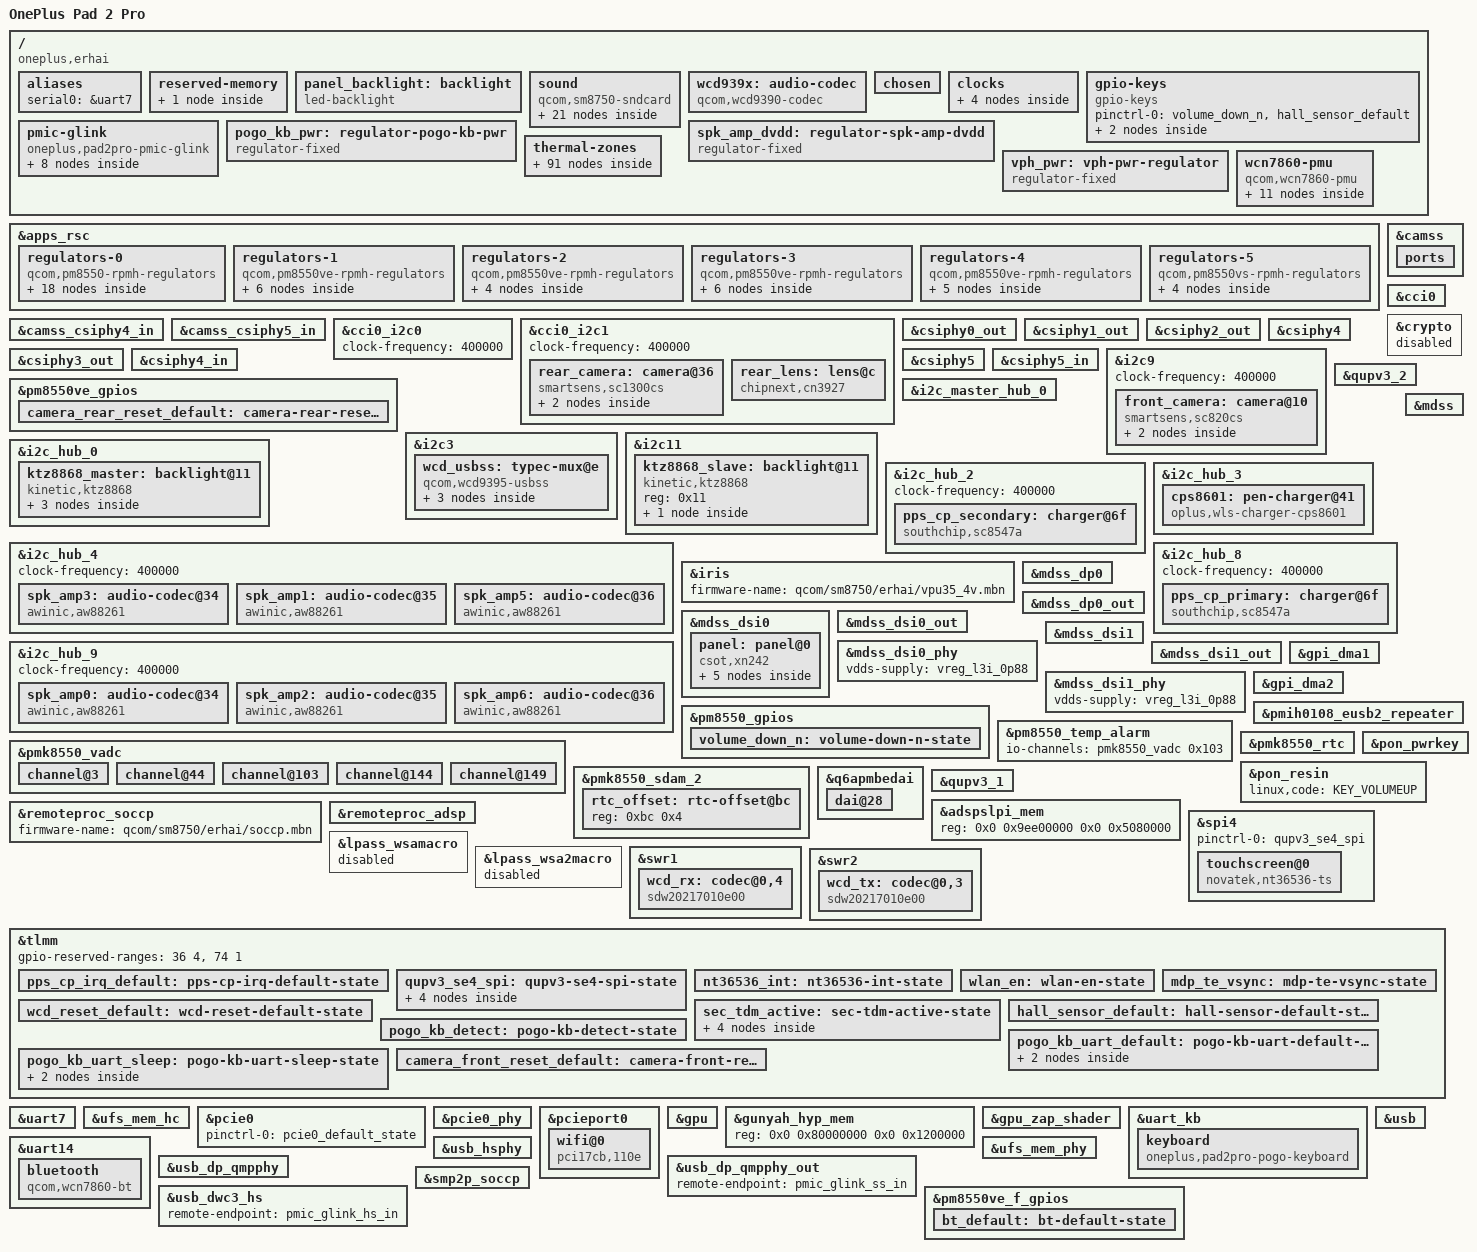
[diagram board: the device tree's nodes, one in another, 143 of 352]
// SPDX-License-Identifier: BSD-3-Clause
/*
 * Copyright (c) 2026, yzddmr6
 */

/dts-v1/;

#include <dt-bindings/clock/qcom,sm8750-cambistmclkcc.h>
#include <dt-bindings/gpio/gpio.h>
#include <dt-bindings/input/gpio-keys.h>
#include <dt-bindings/interrupt-controller/irq.h>
#include <dt-bindings/leds/common.h>
#include <dt-bindings/media/video-interfaces.h>
#include <dt-bindings/regulator/qcom,rpmh-regulator.h>
#include <dt-bindings/thermal/thermal.h>
#include "sm8750.dtsi"
#include "pm8550.dtsi"
#define PMK8550VE_SID 8
#include "pm8550ve.dtsi"
#include "pmih0108.dtsi"
#include "pmk8550.dtsi"
#include "sm8750-pmics.dtsi"

/delete-node/ &cpusys_vm_mem;

/ {
	model = "OnePlus Pad 2 Pro";
	compatible = "oneplus,erhai", "qcom,sm8750";
	chassis-type = "tablet";

	aliases {
		serial0 = &uart7;
	};

	reserved-memory {
		ramoops@afff00000 {
			compatible = "ramoops";
			reg = <0xa 0xfff00000 0x0 0x100000>;
			record-size = <0x20000>;
			console-size = <0x40000>;
			pmsg-size = <0x20000>;
		};
	};

	/*
	 * Both KTZ8868 chips light the one panel and always get the same
	 * brightness value. The initial level is the stock default brightness
	 * level 913 mapped through the stock kernel's backlight table.
	 */
	panel_backlight: backlight {
		compatible = "led-backlight";
		leds = <&ktz8868_master_led>, <&ktz8868_slave_led>;
		default-brightness-level = <1433>;
	};

	sound {
		compatible = "qcom,sm8750-sndcard", "qcom,sm8450-sndcard";
		model = "OnePlus-Pad-2-Pro";
		audio-routing = "IN1_HPHL", "HPHL_OUT",
				"IN2_HPHR", "HPHR_OUT",
				"AMIC1", "MIC BIAS1",
				"AMIC2", "MIC BIAS2",
				"AMIC3", "MIC BIAS4",
				"AMIC4", "MIC BIAS3",
				"AMIC5", "MIC BIAS3",
				"TX SWR_INPUT0", "ADC1_OUTPUT",
				"TX SWR_INPUT1", "ADC2_OUTPUT",
				"TX SWR_INPUT2", "ADC3_OUTPUT",
				"TX SWR_INPUT3", "ADC4_OUTPUT";

		pinctrl-0 = <&sec_tdm_active>;
		pinctrl-names = "default";

		displayport-0-dai-link {
			link-name = "DisplayPort0 Playback";
			convert-sample-format = "s24_le";

			cpu {
				sound-dai = <&q6apmbedai DISPLAY_PORT_RX_0>;
			};

			codec {
				sound-dai = <&mdss_dp0>;
			};

			platform {
				sound-dai = <&q6apm>;
			};
		};

		wcd-playback-dai-link {
			link-name = "WCD Playback";

			cpu {
				sound-dai = <&q6apmbedai RX_CODEC_DMA_RX_0>;
			};

			codec {
				sound-dai = <&wcd939x 0>, <&swr1 0>, <&lpass_rxmacro 0>;
			};

			platform {
				sound-dai = <&q6apm>;
			};
		};

		wcd-capture-dai-link {
			link-name = "WCD Capture";

			cpu {
				sound-dai = <&q6apmbedai TX_CODEC_DMA_TX_3>;
			};

			codec {
				sound-dai = <&wcd939x 1>, <&swr2 1>, <&lpass_txmacro 0>;
			};

			platform {
				sound-dai = <&q6apm>;
			};
		};

		/*
		 * Secondary TDM at 48 kHz: eight 32-bit slots, DSP_B framing,
		 * clocks from the SoC. Each amplifier takes the slot equal to
		 * its stock channel index and latches data on the inverted bit
		 * clock edge, as the stock amplifier configuration does.
		 */
		speaker-playback-dai-link {
			link-name = "Speaker Playback";
			dai-format = "dsp_b";
			convert-rate = <48000>;
			convert-channels = <8>;
			convert-sample-format = "s32_le";

			cpu {
				sound-dai = <&q6apmbedai SECONDARY_TDM_RX_0>;
				dai-tdm-slot-num = <8>;
				dai-tdm-slot-width = <32>;
				dai-tdm-slot-rx-mask = <1 1 1 1 1 1 1 1>;
			};

			codec-0 {
				sound-dai = <&spk_amp0>;
				dai-tdm-slot-tx-mask = <1>;
				dai-tdm-slot-rx-mask = <1>;
				bitclock-inversion;
			};

			codec-1 {
				sound-dai = <&spk_amp1>;
				dai-tdm-slot-tx-mask = <0 1>;
				dai-tdm-slot-rx-mask = <0 1>;
				bitclock-inversion;
			};

			codec-2 {
				sound-dai = <&spk_amp2>;
				dai-tdm-slot-tx-mask = <0 0 1>;
				dai-tdm-slot-rx-mask = <0 0 1>;
				bitclock-inversion;
			};

			codec-3 {
				sound-dai = <&spk_amp3>;
				dai-tdm-slot-tx-mask = <0 0 0 1>;
				dai-tdm-slot-rx-mask = <0 0 0 1>;
				bitclock-inversion;
			};

			codec-5 {
				sound-dai = <&spk_amp5>;
				dai-tdm-slot-tx-mask = <0 0 0 0 0 1>;
				dai-tdm-slot-rx-mask = <0 0 0 0 0 1>;
				bitclock-inversion;
			};

			codec-6 {
				sound-dai = <&spk_amp6>;
				dai-tdm-slot-tx-mask = <0 0 0 0 0 0 1>;
				dai-tdm-slot-rx-mask = <0 0 0 0 0 0 1>;
				bitclock-inversion;
			};

			platform {
				sound-dai = <&q6apm>;
			};
		};
	};

	wcd939x: audio-codec {
		compatible = "qcom,wcd9390-codec";
		#sound-dai-cells = <1>;

		pinctrl-0 = <&wcd_reset_default>;
		pinctrl-names = "default";
		reset-gpios = <&tlmm 101 GPIO_ACTIVE_LOW>;

		vdd-buck-supply = <&vreg_l15b_1p8>;
		vdd-rxtx-supply = <&vreg_l15b_1p8>;
		vdd-io-supply = <&vreg_l15b_1p8>;
		vdd-mic-bias-supply = <&vreg_bob1>;
		vdd-px-supply = <&vreg_l2i_1p2>;

		qcom,micbias1-microvolt = <2700000>;
		qcom,micbias2-microvolt = <2700000>;
		qcom,micbias3-microvolt = <2700000>;
		qcom,micbias4-microvolt = <2700000>;
		qcom,rx-device = <&wcd_rx>;
		qcom,tx-device = <&wcd_tx>;
	};

	/* Filled in by the bootloader, which needs the node to exist. */
	chosen {
	};

	clocks {
		xo_board: xo-board {
			compatible = "fixed-clock";
			clock-frequency = <76800000>;
			#clock-cells = <0>;
		};

		sleep_clk: sleep-clk {
			compatible = "fixed-clock";
			clock-frequency = <32000>;
			#clock-cells = <0>;
		};

		bi_tcxo_div2: bi-tcxo-div2-clk {
			compatible = "fixed-factor-clock";
			#clock-cells = <0>;

			clocks = <&rpmhcc RPMH_CXO_CLK>;
			clock-mult = <1>;
			clock-div = <2>;
		};

		bi_tcxo_ao_div2: bi-tcxo-ao-div2-clk {
			compatible = "fixed-factor-clock";
			#clock-cells = <0>;

			clocks = <&rpmhcc RPMH_CXO_CLK_A>;
			clock-mult = <1>;
			clock-div = <2>;
		};
	};

	gpio-keys {
		compatible = "gpio-keys";

		pinctrl-0 = <&volume_down_n>, <&hall_sensor_default>;
		pinctrl-names = "default";

		key-volume-down {
			label = "Volume Down";
			linux,code = <KEY_VOLUMEDOWN>;
			gpios = <&pm8550_gpios 6 GPIO_ACTIVE_LOW>;
			debounce-interval = <15>;
			linux,can-disable;
			wakeup-source;
		};

		/*
		 * BU52053NVX hall switch behind the cover magnet. The stock
		 * sensor configuration routes it to TLMM pin 97 with no pull;
		 * its supply is the sensor I/O rail, which stays on without
		 * sensor clients.
		 */
		switch-lid {
			label = "Cover";
			gpios = <&tlmm 97 GPIO_ACTIVE_LOW>;
			linux,input-type = <EV_SW>;
			linux,code = <SW_LID>;
			linux,can-disable;
			wakeup-source;
			wakeup-event-action = <EV_ACT_DEASSERTED>;
		};
	};

	pmic-glink {
		compatible = "oneplus,pad2pro-pmic-glink",
			     "qcom,sm8750-pmic-glink",
			     "qcom,sm8550-pmic-glink",
			     "qcom,pmic-glink";
		#address-cells = <1>;
		#size-cells = <0>;

		connector@0 {
			compatible = "usb-c-connector";
			reg = <0>;

			power-role = "dual";
			data-role = "dual";

			ports {
				#address-cells = <1>;
				#size-cells = <0>;

				port@0 {
					reg = <0>;

					pmic_glink_hs_in: endpoint {
						remote-endpoint = <&usb_dwc3_hs>;
					};
				};

				port@1 {
					reg = <1>;

					pmic_glink_ss_in: endpoint {
						remote-endpoint = <&usb_dp_qmpphy_out>;
					};
				};

				port@2 {
					reg = <2>;

					pmic_glink_sbu: endpoint {
						remote-endpoint = <&wcd_usbss_sbu_mux>;
					};
				};
			};
		};
	};

	/*
	 * Switched supply of the keyboard pogo pin connector. The keyboard
	 * driver keeps it off until the attach sense line reports a keyboard.
	 */
	pogo_kb_pwr: regulator-pogo-kb-pwr {
		compatible = "regulator-fixed";
		regulator-name = "pogo_kb_pwr";
		gpio = <&tlmm 85 GPIO_ACTIVE_HIGH>;
		enable-active-high;
	};

	/*
	 * Placeholder for the DVDD input of the six AW88261 amplifiers. The
	 * stock DT gives the amplifiers no supply and its driver requests none;
	 * their chip IDs read back on both stock and mainline without any
	 * consumer holding a rail, which suggests DVDD is up whenever the SoC
	 * runs. Which PMIC output feeds it is unknown, so no voltage, parent
	 * supply or control is described here. Replace this node with that
	 * output once it is identified.
	 */
	spk_amp_dvdd: regulator-spk-amp-dvdd {
		compatible = "regulator-fixed";
		regulator-name = "spk_amp_dvdd";
		regulator-always-on;
		regulator-boot-on;
	};

	thermal-zones {
		/*
		 * The stock tree pauses a CPU core when one of its two sensors
		 * reaches 118 C and takes the core offline at 120 C (C.34
		 * vendor_boot DTB for SM8750P, cpu-*-* zones). Mainline has no
		 * pause or hotplug cooling devices, so a passive trip at the first
		 * of these temperatures throttles the frequency domain of the core
		 * instead; the zones keep their 120 C hot and 125 C critical trips.
		 */
		cpu-0-0-0-thermal {
			polling-delay-passive = <250>;

			trips {
				cpu_0_0_0_alert: trip-point1 {
					temperature = <118000>;
					hysteresis = <8000>;
					type = "passive";
				};
			};

			cooling-maps {
				map0 {
					trip = <&cpu_0_0_0_alert>;
					cooling-device = <&cpu0 THERMAL_NO_LIMIT THERMAL_NO_LIMIT>,
							 <&cpu1 THERMAL_NO_LIMIT THERMAL_NO_LIMIT>,
							 <&cpu2 THERMAL_NO_LIMIT THERMAL_NO_LIMIT>,
							 <&cpu3 THERMAL_NO_LIMIT THERMAL_NO_LIMIT>,
							 <&cpu4 THERMAL_NO_LIMIT THERMAL_NO_LIMIT>,
							 <&cpu5 THERMAL_NO_LIMIT THERMAL_NO_LIMIT>;
				};
			};
		};

		cpu-0-0-1-thermal {
			polling-delay-passive = <250>;

			trips {
				cpu_0_0_1_alert: trip-point1 {
					temperature = <118000>;
					hysteresis = <8000>;
					type = "passive";
				};
			};

			cooling-maps {
				map0 {
					trip = <&cpu_0_0_1_alert>;
					cooling-device = <&cpu0 THERMAL_NO_LIMIT THERMAL_NO_LIMIT>,
							 <&cpu1 THERMAL_NO_LIMIT THERMAL_NO_LIMIT>,
							 <&cpu2 THERMAL_NO_LIMIT THERMAL_NO_LIMIT>,
							 <&cpu3 THERMAL_NO_LIMIT THERMAL_NO_LIMIT>,
							 <&cpu4 THERMAL_NO_LIMIT THERMAL_NO_LIMIT>,
							 <&cpu5 THERMAL_NO_LIMIT THERMAL_NO_LIMIT>;
				};
			};
		};

		cpu-0-1-0-thermal {
			polling-delay-passive = <250>;

			trips {
				cpu_0_1_0_alert: trip-point1 {
					temperature = <118000>;
					hysteresis = <8000>;
					type = "passive";
				};
			};

			cooling-maps {
				map0 {
					trip = <&cpu_0_1_0_alert>;
					cooling-device = <&cpu0 THERMAL_NO_LIMIT THERMAL_NO_LIMIT>,
							 <&cpu1 THERMAL_NO_LIMIT THERMAL_NO_LIMIT>,
							 <&cpu2 THERMAL_NO_LIMIT THERMAL_NO_LIMIT>,
							 <&cpu3 THERMAL_NO_LIMIT THERMAL_NO_LIMIT>,
							 <&cpu4 THERMAL_NO_LIMIT THERMAL_NO_LIMIT>,
							 <&cpu5 THERMAL_NO_LIMIT THERMAL_NO_LIMIT>;
				};
			};
		};

		cpu-0-1-1-thermal {
			polling-delay-passive = <250>;

			trips {
				cpu_0_1_1_alert: trip-point1 {
					temperature = <118000>;
					hysteresis = <8000>;
					type = "passive";
				};
			};

			cooling-maps {
				map0 {
					trip = <&cpu_0_1_1_alert>;
					cooling-device = <&cpu0 THERMAL_NO_LIMIT THERMAL_NO_LIMIT>,
							 <&cpu1 THERMAL_NO_LIMIT THERMAL_NO_LIMIT>,
							 <&cpu2 THERMAL_NO_LIMIT THERMAL_NO_LIMIT>,
							 <&cpu3 THERMAL_NO_LIMIT THERMAL_NO_LIMIT>,
							 <&cpu4 THERMAL_NO_LIMIT THERMAL_NO_LIMIT>,
							 <&cpu5 THERMAL_NO_LIMIT THERMAL_NO_LIMIT>;
				};
			};
		};

		cpu-0-2-0-thermal {
			polling-delay-passive = <250>;

			trips {
				cpu_0_2_0_alert: trip-point1 {
					temperature = <118000>;
					hysteresis = <8000>;
					type = "passive";
				};
			};

			cooling-maps {
				map0 {
					trip = <&cpu_0_2_0_alert>;
					cooling-device = <&cpu0 THERMAL_NO_LIMIT THERMAL_NO_LIMIT>,
							 <&cpu1 THERMAL_NO_LIMIT THERMAL_NO_LIMIT>,
							 <&cpu2 THERMAL_NO_LIMIT THERMAL_NO_LIMIT>,
							 <&cpu3 THERMAL_NO_LIMIT THERMAL_NO_LIMIT>,
							 <&cpu4 THERMAL_NO_LIMIT THERMAL_NO_LIMIT>,
							 <&cpu5 THERMAL_NO_LIMIT THERMAL_NO_LIMIT>;
				};
			};
		};

		cpu-0-2-1-thermal {
			polling-delay-passive = <250>;

			trips {
				cpu_0_2_1_alert: trip-point1 {
					temperature = <118000>;
					hysteresis = <8000>;
					type = "passive";
				};
			};

			cooling-maps {
				map0 {
					trip = <&cpu_0_2_1_alert>;
					cooling-device = <&cpu0 THERMAL_NO_LIMIT THERMAL_NO_LIMIT>,
							 <&cpu1 THERMAL_NO_LIMIT THERMAL_NO_LIMIT>,
							 <&cpu2 THERMAL_NO_LIMIT THERMAL_NO_LIMIT>,
							 <&cpu3 THERMAL_NO_LIMIT THERMAL_NO_LIMIT>,
							 <&cpu4 THERMAL_NO_LIMIT THERMAL_NO_LIMIT>,
							 <&cpu5 THERMAL_NO_LIMIT THERMAL_NO_LIMIT>;
				};
			};
		};

		cpu-0-3-0-thermal {
			polling-delay-passive = <250>;

			trips {
				cpu_0_3_0_alert: trip-point1 {
					temperature = <118000>;
					hysteresis = <8000>;
					type = "passive";
				};
			};

			cooling-maps {
				map0 {
					trip = <&cpu_0_3_0_alert>;
					cooling-device = <&cpu0 THERMAL_NO_LIMIT THERMAL_NO_LIMIT>,
							 <&cpu1 THERMAL_NO_LIMIT THERMAL_NO_LIMIT>,
							 <&cpu2 THERMAL_NO_LIMIT THERMAL_NO_LIMIT>,
							 <&cpu3 THERMAL_NO_LIMIT THERMAL_NO_LIMIT>,
							 <&cpu4 THERMAL_NO_LIMIT THERMAL_NO_LIMIT>,
							 <&cpu5 THERMAL_NO_LIMIT THERMAL_NO_LIMIT>;
				};
			};
		};

		cpu-0-3-1-thermal {
			polling-delay-passive = <250>;

			trips {
				cpu_0_3_1_alert: trip-point1 {
					temperature = <118000>;
					hysteresis = <8000>;
					type = "passive";
				};
			};

			cooling-maps {
				map0 {
					trip = <&cpu_0_3_1_alert>;
					cooling-device = <&cpu0 THERMAL_NO_LIMIT THERMAL_NO_LIMIT>,
							 <&cpu1 THERMAL_NO_LIMIT THERMAL_NO_LIMIT>,
							 <&cpu2 THERMAL_NO_LIMIT THERMAL_NO_LIMIT>,
							 <&cpu3 THERMAL_NO_LIMIT THERMAL_NO_LIMIT>,
							 <&cpu4 THERMAL_NO_LIMIT THERMAL_NO_LIMIT>,
							 <&cpu5 THERMAL_NO_LIMIT THERMAL_NO_LIMIT>;
				};
			};
		};

		cpu-0-4-0-thermal {
			polling-delay-passive = <250>;

			trips {
				cpu_0_4_0_alert: trip-point1 {
					temperature = <118000>;
					hysteresis = <8000>;
					type = "passive";
				};
			};

			cooling-maps {
				map0 {
					trip = <&cpu_0_4_0_alert>;
					cooling-device = <&cpu0 THERMAL_NO_LIMIT THERMAL_NO_LIMIT>,
							 <&cpu1 THERMAL_NO_LIMIT THERMAL_NO_LIMIT>,
							 <&cpu2 THERMAL_NO_LIMIT THERMAL_NO_LIMIT>,
							 <&cpu3 THERMAL_NO_LIMIT THERMAL_NO_LIMIT>,
							 <&cpu4 THERMAL_NO_LIMIT THERMAL_NO_LIMIT>,
							 <&cpu5 THERMAL_NO_LIMIT THERMAL_NO_LIMIT>;
				};
			};
		};

		cpu-0-4-1-thermal {
			polling-delay-passive = <250>;

			trips {
				cpu_0_4_1_alert: trip-point1 {
					temperature = <118000>;
					hysteresis = <8000>;
					type = "passive";
				};
			};

			cooling-maps {
				map0 {
					trip = <&cpu_0_4_1_alert>;
					cooling-device = <&cpu0 THERMAL_NO_LIMIT THERMAL_NO_LIMIT>,
							 <&cpu1 THERMAL_NO_LIMIT THERMAL_NO_LIMIT>,
							 <&cpu2 THERMAL_NO_LIMIT THERMAL_NO_LIMIT>,
							 <&cpu3 THERMAL_NO_LIMIT THERMAL_NO_LIMIT>,
							 <&cpu4 THERMAL_NO_LIMIT THERMAL_NO_LIMIT>,
							 <&cpu5 THERMAL_NO_LIMIT THERMAL_NO_LIMIT>;
				};
			};
		};

		cpu-0-5-0-thermal {
			polling-delay-passive = <250>;

			trips {
				cpu_0_5_0_alert: trip-point1 {
					temperature = <118000>;
					hysteresis = <8000>;
					type = "passive";
				};
			};

			cooling-maps {
				map0 {
					trip = <&cpu_0_5_0_alert>;
					cooling-device = <&cpu0 THERMAL_NO_LIMIT THERMAL_NO_LIMIT>,
							 <&cpu1 THERMAL_NO_LIMIT THERMAL_NO_LIMIT>,
							 <&cpu2 THERMAL_NO_LIMIT THERMAL_NO_LIMIT>,
							 <&cpu3 THERMAL_NO_LIMIT THERMAL_NO_LIMIT>,
							 <&cpu4 THERMAL_NO_LIMIT THERMAL_NO_LIMIT>,
							 <&cpu5 THERMAL_NO_LIMIT THERMAL_NO_LIMIT>;
				};
			};
		};

		cpu-0-5-1-thermal {
			polling-delay-passive = <250>;

			trips {
				cpu_0_5_1_alert: trip-point1 {
					temperature = <118000>;
					hysteresis = <8000>;
					type = "passive";
				};
			};

			cooling-maps {
				map0 {
					trip = <&cpu_0_5_1_alert>;
					cooling-device = <&cpu0 THERMAL_NO_LIMIT THERMAL_NO_LIMIT>,
							 <&cpu1 THERMAL_NO_LIMIT THERMAL_NO_LIMIT>,
							 <&cpu2 THERMAL_NO_LIMIT THERMAL_NO_LIMIT>,
							 <&cpu3 THERMAL_NO_LIMIT THERMAL_NO_LIMIT>,
							 <&cpu4 THERMAL_NO_LIMIT THERMAL_NO_LIMIT>,
							 <&cpu5 THERMAL_NO_LIMIT THERMAL_NO_LIMIT>;
				};
			};
		};

		cpu-1-0-0-thermal {
			polling-delay-passive = <250>;

			trips {
				cpu_1_0_0_alert: trip-point1 {
					temperature = <118000>;
					hysteresis = <8000>;
					type = "passive";
				};
			};

			cooling-maps {
				map0 {
					trip = <&cpu_1_0_0_alert>;
					cooling-device = <&cpu6 THERMAL_NO_LIMIT THERMAL_NO_LIMIT>,
							 <&cpu7 THERMAL_NO_LIMIT THERMAL_NO_LIMIT>;
				};
			};
		};

		cpu-1-0-1-thermal {
			polling-delay-passive = <250>;

			trips {
				cpu_1_0_1_alert: trip-point1 {
					temperature = <118000>;
					hysteresis = <8000>;
					type = "passive";
				};
			};

			cooling-maps {
				map0 {
					trip = <&cpu_1_0_1_alert>;
					cooling-device = <&cpu6 THERMAL_NO_LIMIT THERMAL_NO_LIMIT>,
							 <&cpu7 THERMAL_NO_LIMIT THERMAL_NO_LIMIT>;
				};
			};
		};

		cpu-1-1-0-thermal {
			polling-delay-passive = <250>;

			trips {
				cpu_1_1_0_alert: trip-point1 {
					temperature = <118000>;
					hysteresis = <8000>;
					type = "passive";
				};
			};

			cooling-maps {
				map0 {
					trip = <&cpu_1_1_0_alert>;
					cooling-device = <&cpu6 THERMAL_NO_LIMIT THERMAL_NO_LIMIT>,
							 <&cpu7 THERMAL_NO_LIMIT THERMAL_NO_LIMIT>;
				};
			};
		};

		cpu-1-1-1-thermal {
			polling-delay-passive = <250>;

			trips {
				cpu_1_1_1_alert: trip-point1 {
					temperature = <118000>;
					hysteresis = <8000>;
					type = "passive";
				};
			};

			cooling-maps {
				map0 {
					trip = <&cpu_1_1_1_alert>;
					cooling-device = <&cpu6 THERMAL_NO_LIMIT THERMAL_NO_LIMIT>,
							 <&cpu7 THERMAL_NO_LIMIT THERMAL_NO_LIMIT>;
				};
			};
		};

		gpio2-thermal {
			thermal-sensors = <&pmk8550_vadc 0x149>;
		};

		skin-thermal {
			thermal-sensors = <&pmk8550_vadc 0x144>;
		};

		/*
		 * Trips and actions follow the stock sys-therm-0 zone on the
		 * same thermistor (C.34 dtbo, qcom/sun-pmic-overlay.dtsi and
		 * qcom/sun-thermal-overlay.dtsi). At 88 C stock pauses CPUs 2-7,
		 * caps the GPU at power level 5 and mitigates the CDSP; at 90 C
		 * it also offlines CPUs 3-7 and mitigates the modem. Mainline
		 * has no CPU pause/hotplug or CDSP/modem cooling devices here,
		 * so both trips throttle the two CPU frequency domains instead.
		 * GPU cooling state 5 is the same 734 MHz level as stock, the
		 * speed bin having the same 14 levels on both kernels.
		 */
		xo-thermal {
			polling-delay-passive = <5000>;

			thermal-sensors = <&pmk8550_vadc 0x44>;

			trips {
				xo_alert0: trip-point0 {
					temperature = <88000>;
					hysteresis = <8000>;
					type = "passive";
				};

				xo_alert1: trip-point1 {
					temperature = <90000>;
					hysteresis = <10000>;
					type = "passive";
				};

				trip-point2 {
					temperature = <100000>;
					hysteresis = <0>;
					type = "hot";
				};
			};

			cooling-maps {
				map0 {
					trip = <&xo_alert0>;
					cooling-device = <&cpu0 THERMAL_NO_LIMIT THERMAL_NO_LIMIT>,
							 <&cpu1 THERMAL_NO_LIMIT THERMAL_NO_LIMIT>,
							 <&cpu2 THERMAL_NO_LIMIT THERMAL_NO_LIMIT>,
							 <&cpu3 THERMAL_NO_LIMIT THERMAL_NO_LIMIT>,
							 <&cpu4 THERMAL_NO_LIMIT THERMAL_NO_LIMIT>,
							 <&cpu5 THERMAL_NO_LIMIT THERMAL_NO_LIMIT>,
							 <&cpu6 THERMAL_NO_LIMIT THERMAL_NO_LIMIT>,
							 <&cpu7 THERMAL_NO_LIMIT THERMAL_NO_LIMIT>;
				};

				map1 {
					trip = <&xo_alert0>;
					cooling-device = <&gpu 5 THERMAL_NO_LIMIT>;
				};

				map2 {
					trip = <&xo_alert1>;
					cooling-device = <&cpu0 THERMAL_NO_LIMIT THERMAL_NO_LIMIT>,
							 <&cpu1 THERMAL_NO_LIMIT THERMAL_NO_LIMIT>,
							 <&cpu2 THERMAL_NO_LIMIT THERMAL_NO_LIMIT>,
							 <&cpu3 THERMAL_NO_LIMIT THERMAL_NO_LIMIT>,
							 <&cpu4 THERMAL_NO_LIMIT THERMAL_NO_LIMIT>,
							 <&cpu5 THERMAL_NO_LIMIT THERMAL_NO_LIMIT>,
							 <&cpu6 THERMAL_NO_LIMIT THERMAL_NO_LIMIT>,
							 <&cpu7 THERMAL_NO_LIMIT THERMAL_NO_LIMIT>;
				};
			};
		};
	};

	vph_pwr: vph-pwr-regulator {
		compatible = "regulator-fixed";

		regulator-name = "vph_pwr";
		regulator-min-microvolt = <3700000>;
		regulator-max-microvolt = <3700000>;

		regulator-always-on;
		regulator-boot-on;
	};

	/* WCN7860 combo chip on pcie0 (stock: qcom,cnss-peach). Rails and
	 * enables match the stock mapping: wlan-en gpio16, bt-en pm8550ve_f
	 * gpio3, io=L3F io12=L2F aon=S4D dig=S5F rfa1p2=S7I rfa1p8=S3G. */
	wcn7860-pmu {
		compatible = "qcom,wcn7860-pmu";

		pinctrl-names = "default";
		pinctrl-0 = <&wlan_en>, <&bt_default>;

		wlan-enable-gpios = <&tlmm 16 GPIO_ACTIVE_HIGH>;
		bt-enable-gpios = <&pm8550ve_f_gpios 3 GPIO_ACTIVE_HIGH>;

		vddio-supply = <&vreg_l3f_1p8>;
		vddio1p2-supply = <&vreg_l2f_1p2>;
		vddaon-supply = <&vreg_s4d_0p85>;
		vdddig-supply = <&vreg_s5f_0p85>;
		vddrfa1p2-supply = <&vreg_s7i_1p2>;
		vddrfa1p8-supply = <&vreg_s3g_1p8>;

		regulators {
			vreg_pmu_rfa_cmn: ldo0 {
				regulator-name = "vreg_pmu_rfa_cmn";
			};

			vreg_pmu_aon_0p59: ldo1 {
				regulator-name = "vreg_pmu_aon_0p59";
			};

			vreg_pmu_wlcx_0p8: ldo2 {
				regulator-name = "vreg_pmu_wlcx_0p8";
			};

			vreg_pmu_wlmx_0p85: ldo3 {
				regulator-name = "vreg_pmu_wlmx_0p85";
			};

			vreg_pmu_btcmx_0p85: ldo4 {
				regulator-name = "vreg_pmu_btcmx_0p85";
			};

			vreg_pmu_rfa_0p8: ldo5 {
				regulator-name = "vreg_pmu_rfa_0p8";
			};

			vreg_pmu_rfa_1p2: ldo6 {
				regulator-name = "vreg_pmu_rfa_1p2";
			};

			vreg_pmu_rfa_1p8: ldo7 {
				regulator-name = "vreg_pmu_rfa_1p8";
			};

			vreg_pmu_pcie_0p9: ldo8 {
				regulator-name = "vreg_pmu_pcie_0p9";
			};

			vreg_pmu_pcie_1p8: ldo9 {
				regulator-name = "vreg_pmu_pcie_1p8";
			};
		};
	};
};

&apps_rsc {
	regulators-0 {
		compatible = "qcom,pm8550-rpmh-regulators";

		vdd-bob1-supply = <&vph_pwr>;
		vdd-bob2-supply = <&vph_pwr>;
		vdd-l1-l4-l10-supply = <&vreg_s3g_1p8>;
		vdd-l2-l13-l14-supply = <&vreg_bob1>;
		vdd-l3-supply = <&vreg_s7i_1p2>;
		vdd-l5-l16-supply = <&vreg_bob1>;
		vdd-l6-l7-supply = <&vreg_bob1>;
		vdd-l8-l9-supply = <&vreg_bob1>;
		vdd-l11-supply = <&vreg_s7i_1p2>;
		vdd-l12-supply = <&vreg_s3g_1p8>;
		vdd-l15-supply = <&vreg_s3g_1p8>;
		vdd-l17-supply = <&vreg_bob2>;

		qcom,pmic-id = "b";

		vreg_bob1: bob1 {
			regulator-name = "vreg_bob1";
			regulator-min-microvolt = <3008000>;
			regulator-max-microvolt = <4000000>;
			regulator-initial-mode = <RPMH_REGULATOR_MODE_HPM>;
		};

		vreg_bob2: bob2 {
			regulator-name = "vreg_bob2";
			regulator-min-microvolt = <2704000>;
			regulator-max-microvolt = <3008000>;
			regulator-initial-mode = <RPMH_REGULATOR_MODE_HPM>;
		};

		vreg_l1b_1p8: ldo1 {
			regulator-name = "vreg_l1b_1p8";
			regulator-min-microvolt = <1800000>;
			regulator-max-microvolt = <1800000>;
			regulator-initial-mode = <RPMH_REGULATOR_MODE_HPM>;
			regulator-allow-set-load;
			regulator-allowed-modes = <RPMH_REGULATOR_MODE_LPM
						   RPMH_REGULATOR_MODE_HPM>;
		};

		vreg_l2b_3p0: ldo2 {
			regulator-name = "vreg_l2b_3p0";
			regulator-min-microvolt = <3008000>;
			regulator-max-microvolt = <3048000>;
			regulator-initial-mode = <RPMH_REGULATOR_MODE_HPM>;
			regulator-allow-set-load;
			regulator-allowed-modes = <RPMH_REGULATOR_MODE_LPM
						   RPMH_REGULATOR_MODE_HPM>;
		};

		vreg_l4b_1p8: ldo4 {
			regulator-name = "vreg_l4b_1p8";
			regulator-min-microvolt = <1800000>;
			regulator-max-microvolt = <1800000>;
			regulator-initial-mode = <RPMH_REGULATOR_MODE_HPM>;
			regulator-allow-set-load;
			regulator-allowed-modes = <RPMH_REGULATOR_MODE_LPM
						   RPMH_REGULATOR_MODE_HPM>;
		};

		vreg_l5b_3p1: ldo5 {
			regulator-name = "vreg_l5b_3p1";
			regulator-min-microvolt = <3100000>;
			regulator-max-microvolt = <3148000>;
			regulator-initial-mode = <RPMH_REGULATOR_MODE_HPM>;
			regulator-allow-set-load;
			regulator-allowed-modes = <RPMH_REGULATOR_MODE_LPM
						   RPMH_REGULATOR_MODE_HPM>;
		};

		vreg_l6b_1p8: ldo6 {
			regulator-name = "vreg_l6b_1p8";
			regulator-min-microvolt = <1800000>;
			regulator-max-microvolt = <3008000>;
			regulator-initial-mode = <RPMH_REGULATOR_MODE_HPM>;
			regulator-allow-set-load;
			regulator-allowed-modes = <RPMH_REGULATOR_MODE_LPM
						   RPMH_REGULATOR_MODE_HPM>;
		};

		vreg_l7b_1p8: ldo7 {
			regulator-name = "vreg_l7b_1p8";
			regulator-min-microvolt = <1800000>;
			regulator-max-microvolt = <3008000>;
			regulator-initial-mode = <RPMH_REGULATOR_MODE_HPM>;
			regulator-allow-set-load;
			regulator-allowed-modes = <RPMH_REGULATOR_MODE_LPM
						   RPMH_REGULATOR_MODE_HPM>;

		};

		vreg_l8b_1p8: ldo8 {
			regulator-name = "vreg_l8b_1p8";
			regulator-min-microvolt = <1800000>;
			regulator-max-microvolt = <3008000>;
			regulator-initial-mode = <RPMH_REGULATOR_MODE_HPM>;
			regulator-allow-set-load;
			regulator-allowed-modes = <RPMH_REGULATOR_MODE_LPM
						   RPMH_REGULATOR_MODE_HPM>;
		};

		vreg_l9b_2p9: ldo9 {
			regulator-name = "vreg_l9b_2p9";
			regulator-min-microvolt = <2800000>;
			regulator-max-microvolt = <2800000>;
			regulator-initial-mode = <RPMH_REGULATOR_MODE_HPM>;
			regulator-allow-set-load;
			regulator-allowed-modes = <RPMH_REGULATOR_MODE_LPM
						   RPMH_REGULATOR_MODE_HPM>;
		};

		vreg_l10b_1p8: ldo10 {
			regulator-name = "vreg_l10b_1p8";
			regulator-min-microvolt = <1800000>;
			regulator-max-microvolt = <1800000>;
			regulator-initial-mode = <RPMH_REGULATOR_MODE_HPM>;
			regulator-allow-set-load;
			regulator-allowed-modes = <RPMH_REGULATOR_MODE_LPM
						   RPMH_REGULATOR_MODE_HPM>;
		};

		vreg_l11b_1p0: ldo11 {
			regulator-name = "vreg_l11b_1p0";
			regulator-min-microvolt = <1200000>;
			regulator-max-microvolt = <1200000>;
			regulator-initial-mode = <RPMH_REGULATOR_MODE_HPM>;
			regulator-allow-set-load;
			regulator-allowed-modes = <RPMH_REGULATOR_MODE_LPM
						   RPMH_REGULATOR_MODE_HPM>;
		};

		vreg_l12b_1p8: ldo12 {
			regulator-name = "vreg_l12b_1p8";
			/*
			 * Panel/touch vddio; the stock display supply entry for this
			 * board asks for 1.9V. The nldo515 8mV grid has no 1.9V step
			 * (an unsatisfiable constraint fails the whole PMIC), so take
			 * the step just below. The panel switches it together with
			 * the LCD bias; the touch controller in the same die is only
			 * used while the panel is prepared.
			 */
			regulator-min-microvolt = <1896000>;
			regulator-max-microvolt = <1904000>;
			regulator-initial-mode = <RPMH_REGULATOR_MODE_HPM>;
			regulator-allow-set-load;
			regulator-allowed-modes = <RPMH_REGULATOR_MODE_LPM
						   RPMH_REGULATOR_MODE_HPM>;
		};

		vreg_l13b_3p0: ldo13 {
			regulator-name = "vreg_l13b_3p0";
			regulator-min-microvolt = <3000000>;
			regulator-max-microvolt = <3000000>;
			regulator-initial-mode = <RPMH_REGULATOR_MODE_HPM>;
			regulator-allow-set-load;
			regulator-allowed-modes = <RPMH_REGULATOR_MODE_LPM
						   RPMH_REGULATOR_MODE_HPM>;
		};

		vreg_l14b_3p2: ldo14 {
			regulator-name = "vreg_l14b_3p2";
			regulator-min-microvolt = <3200000>;
			regulator-max-microvolt = <3200000>;
			regulator-initial-mode = <RPMH_REGULATOR_MODE_HPM>;
			regulator-allow-set-load;
			regulator-allowed-modes = <RPMH_REGULATOR_MODE_LPM
						   RPMH_REGULATOR_MODE_HPM>;
		};

		vreg_l15b_1p8: ldo15 {
			regulator-name = "vreg_l15b_1p8";
			regulator-min-microvolt = <1800000>;
			regulator-max-microvolt = <1800000>;
			regulator-initial-mode = <RPMH_REGULATOR_MODE_HPM>;
			regulator-allow-set-load;
			regulator-allowed-modes = <RPMH_REGULATOR_MODE_LPM
						   RPMH_REGULATOR_MODE_HPM>;
		};

		vreg_l16b_2p8: ldo16 {
			regulator-name = "vreg_l16b_2p8";
			regulator-min-microvolt = <2800000>;
			regulator-max-microvolt = <2800000>;
			regulator-initial-mode = <RPMH_REGULATOR_MODE_HPM>;
			regulator-allow-set-load;
			regulator-allowed-modes = <RPMH_REGULATOR_MODE_LPM
						   RPMH_REGULATOR_MODE_HPM>;
		};

		vreg_l17b_2p5: ldo17 {
			regulator-name = "vreg_l17b_2p5";
			regulator-min-microvolt = <2504000>;
			regulator-max-microvolt = <2504000>;
			regulator-initial-mode = <RPMH_REGULATOR_MODE_HPM>;
			regulator-allow-set-load;
			regulator-allowed-modes = <RPMH_REGULATOR_MODE_LPM
						   RPMH_REGULATOR_MODE_HPM>;
		};
	};

	regulators-1 {
		compatible = "qcom,pm8550ve-rpmh-regulators";

		vdd-l1-supply = <&vreg_s7i_1p2>;
		vdd-l2-supply = <&vreg_s1d_0p97>;
		vdd-l3-supply = <&vreg_s1d_0p97>;
		vdd-s1-supply = <&vph_pwr>;
		vdd-s3-supply = <&vph_pwr>;
		vdd-s4-supply = <&vph_pwr>;

		qcom,pmic-id = "d";

		vreg_s1d_0p97: smps1 {
			regulator-name = "vreg_s1d_0p97";
			regulator-min-microvolt = <880000>;
			regulator-max-microvolt = <1100000>;
			regulator-initial-mode = <RPMH_REGULATOR_MODE_HPM>;
		};

		vreg_s3d_1p2: smps3 {
			regulator-name = "vreg_s3d_1p2";
			regulator-min-microvolt = <1200000>;
			regulator-max-microvolt = <1300000>;
			regulator-initial-mode = <RPMH_REGULATOR_MODE_HPM>;
		};

		vreg_s4d_0p85: smps4 {
			regulator-name = "vreg_s4d_0p85";
			regulator-min-microvolt = <852000>;
			regulator-max-microvolt = <1036000>;
			regulator-initial-mode = <RPMH_REGULATOR_MODE_HPM>;
		};

		vreg_l1d_1p2: ldo1 {
			regulator-name = "vreg_l1d_1p2";
			regulator-min-microvolt = <1200000>;
			regulator-max-microvolt = <1200000>;
			regulator-initial-mode = <RPMH_REGULATOR_MODE_HPM>;
			regulator-allow-set-load;
			regulator-allowed-modes = <RPMH_REGULATOR_MODE_LPM
						   RPMH_REGULATOR_MODE_HPM>;
		};

		vreg_l2d_0p88: ldo2 {
			regulator-name = "vreg_l2d_0p88";
			regulator-min-microvolt = <880000>;
			regulator-max-microvolt = <912000>;
			regulator-initial-mode = <RPMH_REGULATOR_MODE_HPM>;
			regulator-allow-set-load;
			regulator-allowed-modes = <RPMH_REGULATOR_MODE_LPM
						   RPMH_REGULATOR_MODE_HPM>;
		};

		vreg_l3d_0p88: ldo3 {
			regulator-name = "vreg_l3d_0p88";
			regulator-min-microvolt = <880000>;
			regulator-max-microvolt = <920000>;
			regulator-initial-mode = <RPMH_REGULATOR_MODE_HPM>;
			regulator-allow-set-load;
			regulator-allowed-modes = <RPMH_REGULATOR_MODE_LPM
						   RPMH_REGULATOR_MODE_HPM>;
		};
	};

	regulators-2 {
		compatible = "qcom,pm8550ve-rpmh-regulators";

		vdd-l1-supply = <&vreg_s1d_0p97>;
		vdd-l2-supply = <&vreg_s7i_1p2>;
		vdd-l3-supply = <&vreg_s3g_1p8>;
		vdd-s5-supply = <&vph_pwr>;

		qcom,pmic-id = "f";

		vreg_s5f_0p85: smps5 {
			regulator-name = "vreg_s5f_0p85";
			regulator-min-microvolt = <852000>;
			regulator-max-microvolt = <1000000>;
			regulator-initial-mode = <RPMH_REGULATOR_MODE_HPM>;
		};

		vreg_l1f_0p88: ldo1 {
			regulator-name = "vreg_l1f_0p88";
			regulator-min-microvolt = <880000>;
			regulator-max-microvolt = <920000>;
			regulator-initial-mode = <RPMH_REGULATOR_MODE_HPM>;
			regulator-allow-set-load;
			regulator-allowed-modes = <RPMH_REGULATOR_MODE_LPM
						   RPMH_REGULATOR_MODE_HPM>;
		};

		vreg_l2f_1p2: ldo2 {
			regulator-name = "vreg_l2f_1p2";
			regulator-min-microvolt = <1200000>;
			regulator-max-microvolt = <1200000>;
			regulator-initial-mode = <RPMH_REGULATOR_MODE_HPM>;
			regulator-allow-set-load;
			regulator-allowed-modes = <RPMH_REGULATOR_MODE_LPM
						   RPMH_REGULATOR_MODE_HPM>;
		};

		vreg_l3f_1p8: ldo3 {
			regulator-name = "vreg_l3f_1p8";
			regulator-min-microvolt = <1800000>;
			regulator-max-microvolt = <1800000>;
			regulator-initial-mode = <RPMH_REGULATOR_MODE_HPM>;
			regulator-allow-set-load;
			regulator-allowed-modes = <RPMH_REGULATOR_MODE_LPM
						   RPMH_REGULATOR_MODE_HPM>;
		};

	};

	regulators-3 {
		compatible = "qcom,pm8550ve-rpmh-regulators";

		vdd-l1-supply = <&vreg_s1d_0p97>;
		vdd-l2-supply = <&vreg_s3g_1p8>;
		vdd-l3-supply = <&vreg_s7i_1p2>;
		vdd-s1-supply = <&vph_pwr>;
		vdd-s3-supply = <&vph_pwr>;

		qcom,pmic-id = "g";

		vreg_s1g_0p5: smps1 {
			regulator-name = "vreg_s1g_0p5";
			regulator-min-microvolt = <300000>;
			regulator-max-microvolt = <700000>;
			regulator-initial-mode = <RPMH_REGULATOR_MODE_HPM>;
		};

		vreg_s3g_1p8: smps3 {
			regulator-name = "vreg_s3g_1p8";
			regulator-min-microvolt = <1856000>;
			regulator-max-microvolt = <2000000>;
			regulator-initial-mode = <RPMH_REGULATOR_MODE_LPM>;
			regulator-allow-set-load;
			regulator-allowed-modes = <RPMH_REGULATOR_MODE_LPM
						   RPMH_REGULATOR_MODE_HPM>;
		};

		vreg_s4g_0p75: smps4 {
			regulator-name = "vreg_s4g_0p75";
			regulator-min-microvolt = <300000>;
			regulator-max-microvolt = <900000>;
			regulator-initial-mode = <RPMH_REGULATOR_MODE_HPM>;
		};

		vreg_l1g_0p91: ldo1 {
			regulator-name = "vreg_l1g_0p91";
			regulator-min-microvolt = <912000>;
			regulator-max-microvolt = <936000>;
			regulator-initial-mode = <RPMH_REGULATOR_MODE_HPM>;
			regulator-allow-set-load;
			regulator-allowed-modes = <RPMH_REGULATOR_MODE_LPM
						   RPMH_REGULATOR_MODE_HPM>;
		};

		vreg_l2g_1p8: ldo2 {
			regulator-name = "vreg_l2g_1p8";
			regulator-min-microvolt = <1200000>;
			regulator-max-microvolt = <1860000>;
			regulator-initial-mode = <RPMH_REGULATOR_MODE_HPM>;
			regulator-allow-set-load;
			regulator-allowed-modes = <RPMH_REGULATOR_MODE_LPM
						   RPMH_REGULATOR_MODE_HPM>;
		};

		vreg_l3g_1p2: ldo3 {
			regulator-name = "vreg_l3g_1p2";
			regulator-min-microvolt = <1200000>;
			regulator-max-microvolt = <1256000>;
			regulator-initial-mode = <RPMH_REGULATOR_MODE_HPM>;
			regulator-allow-set-load;
			regulator-allowed-modes = <RPMH_REGULATOR_MODE_LPM
						   RPMH_REGULATOR_MODE_HPM>;
		};
	};

	regulators-4 {
		compatible = "qcom,pm8550ve-rpmh-regulators";

		vdd-l1-supply = <&vreg_s7i_1p2>;
		vdd-l2-supply = <&vreg_s7i_1p2>;
		vdd-l3-supply = <&vreg_s1d_0p97>;
		vdd-s7-supply = <&vph_pwr>;
		vdd-s8-supply = <&vph_pwr>;

		qcom,pmic-id = "i";

		vreg_s7i_1p2: smps7 {
			regulator-name = "vreg_s7i_1p2";
			regulator-min-microvolt = <1224000>;
			regulator-max-microvolt = <1340000>;
			regulator-initial-mode = <RPMH_REGULATOR_MODE_HPM>;
		};

		vreg_s8i_0p9: smps8 {
			regulator-name = "vreg_s8i_0p9";
			regulator-min-microvolt = <900000>;
			regulator-max-microvolt = <972000>;
			regulator-initial-mode = <RPMH_REGULATOR_MODE_HPM>;
		};

		vreg_l1i_1p2: ldo1 {
			regulator-name = "vreg_l1i_1p2";
			regulator-min-microvolt = <1200000>;
			regulator-max-microvolt = <1200000>;
			regulator-initial-mode = <RPMH_REGULATOR_MODE_HPM>;
			regulator-allow-set-load;
			regulator-allowed-modes = <RPMH_REGULATOR_MODE_LPM
						   RPMH_REGULATOR_MODE_HPM>;
		};

		vreg_l2i_1p2: ldo2 {
			regulator-name = "vreg_l2i_1p2";
			regulator-min-microvolt = <1200000>;
			regulator-max-microvolt = <1200000>;
			regulator-initial-mode = <RPMH_REGULATOR_MODE_HPM>;
			regulator-allow-set-load;
			regulator-allowed-modes = <RPMH_REGULATOR_MODE_LPM
						   RPMH_REGULATOR_MODE_HPM>;
		};

		vreg_l3i_0p88: ldo3 {
			regulator-name = "vreg_l3i_0p88";
			regulator-min-microvolt = <880000>;
			regulator-max-microvolt = <912000>;
			regulator-initial-mode = <RPMH_REGULATOR_MODE_HPM>;
			regulator-allow-set-load;
			regulator-allowed-modes = <RPMH_REGULATOR_MODE_LPM
						   RPMH_REGULATOR_MODE_HPM>;
		};
	};

	regulators-5 {
		compatible = "qcom,pm8550vs-rpmh-regulators";

		vdd-l1-supply = <&vreg_s1d_0p97>;
		vdd-l2-supply = <&vreg_s7i_1p2>;
		vdd-s2-supply = <&vph_pwr>;
		vdd-s3-supply = <&vph_pwr>;
		vdd-s4-supply = <&vph_pwr>;

		qcom,pmic-id = "j";

		vreg_s2j_1p1: smps2 {
			regulator-name = "vreg_s2j_1p1";
			regulator-min-microvolt = <1000000>;
			regulator-max-microvolt = <1100000>;
			regulator-initial-mode = <RPMH_REGULATOR_MODE_HPM>;
		};

		vreg_s3j_1p1: smps3 {
			regulator-name = "vreg_s3j_1p1";
			regulator-min-microvolt = <1000000>;
			regulator-max-microvolt = <1100000>;
			regulator-initial-mode = <RPMH_REGULATOR_MODE_HPM>;
		};

		vreg_l1j_0p91: ldo1 {
			regulator-name = "vreg_l1j_0p91";
			regulator-min-microvolt = <880000>;
			regulator-max-microvolt = <920000>;
			regulator-initial-mode = <RPMH_REGULATOR_MODE_HPM>;
			regulator-allow-set-load;
			regulator-allowed-modes = <RPMH_REGULATOR_MODE_LPM
						   RPMH_REGULATOR_MODE_HPM>;
		};

		vreg_l2j_1p2: ldo2 {
			regulator-name = "vreg_l2j_1p2";
			regulator-min-microvolt = <1200000>;
			regulator-max-microvolt = <1200000>;
			regulator-initial-mode = <RPMH_REGULATOR_MODE_HPM>;
			regulator-allow-set-load;
			regulator-allowed-modes = <RPMH_REGULATOR_MODE_LPM
						   RPMH_REGULATOR_MODE_HPM>;
		};
	};
};

&camss {
	status = "okay";

	ports {
		/delete-node/ port@0;
		/delete-node/ port@1;
		/delete-node/ port@2;
		/delete-node/ port@3;
	};
};

&camss_csiphy4_in {
	bus-type = <MEDIA_BUS_TYPE_CSI2_DPHY>;
	data-lanes = <1 2 3 4>;
};

&camss_csiphy5_in {
	bus-type = <MEDIA_BUS_TYPE_CSI2_DPHY>;
	data-lanes = <1 2 3 4>;
};

&cci0 {
	pinctrl-0 = <&cci0_1_default>;
	pinctrl-1 = <&cci0_1_sleep>;
	status = "okay";
};

&cci0_i2c0 {
	clock-frequency = <400000>;
};

&cci0_i2c1 {
	clock-frequency = <400000>;

	rear_camera: camera@36 {
		compatible = "smartsens,sc1300cs";
		reg = <0x36>;
		clocks = <&cambistmclkcc CAM_BIST_MCLK_CC_MCLK1_CLK>;
		assigned-clocks = <&cambistmclkcc CAM_BIST_MCLK_CC_MCLK1_CLK>;
		assigned-clock-rates = <24000000>;
		pinctrl-names = "default";
		pinctrl-0 = <&cam1_default &camera_rear_reset_default>;
		reset-gpios = <&pm8550ve_gpios 5 GPIO_ACTIVE_LOW>;
		avdd-supply = <&vreg_l16b_2p8>;
		dvdd-supply = <&vreg_l1i_1p2>;
		dovdd-supply = <&vreg_l4b_1p8>;
		lens-focus = <&rear_lens>;
		orientation = <1>;
		rotation = <180>;

		port {
			rear_camera_out: endpoint {
				remote-endpoint = <&csiphy4_in>;
				data-lanes = <1 2 3 4>;
				link-frequencies = /bits/ 64 <600000000>;
			};
		};
	};

	rear_lens: lens@c {
		compatible = "chipnext,cn3927";
		reg = <0x0c>;
		vio-supply = <&vreg_l4b_1p8>;
		vaf-supply = <&vreg_l9b_2p9>;
	};
};

&crypto {
	status = "disabled";
};

&csiphy0_out {
	/delete-property/ remote-endpoint;
};

&csiphy1_out {
	/delete-property/ remote-endpoint;
};

&csiphy2_out {
	/delete-property/ remote-endpoint;
};

&csiphy3_out {
	/delete-property/ remote-endpoint;
};

&csiphy4 {
	vdda-0p9-supply = <&vreg_l3i_0p88>;
	vdda-1p2-supply = <&vreg_l3g_1p2>;
	status = "okay";
};

&csiphy4_in {
	bus-type = <MEDIA_BUS_TYPE_CSI2_DPHY>;
	data-lanes = <1 2 3 4>;
	remote-endpoint = <&rear_camera_out>;
};

&csiphy5 {
	vdda-0p9-supply = <&vreg_l1f_0p88>;
	vdda-1p2-supply = <&vreg_l3g_1p2>;
	status = "okay";
};

&csiphy5_in {
	bus-type = <MEDIA_BUS_TYPE_CSI2_DPHY>;
	data-lanes = <1 2 3 4>;
	remote-endpoint = <&front_camera_out>;
};

&i2c9 {
	clock-frequency = <400000>;
	status = "okay";

	front_camera: camera@10 {
		compatible = "smartsens,sc820cs";
		reg = <0x10>;
		clocks = <&cambistmclkcc CAM_BIST_MCLK_CC_MCLK4_CLK>;
		assigned-clocks = <&cambistmclkcc CAM_BIST_MCLK_CC_MCLK4_CLK>;
		assigned-clock-rates = <24000000>;
		pinctrl-names = "default";
		pinctrl-0 = <&cam4_default &camera_front_reset_default>;
		reset-gpios = <&tlmm 7 GPIO_ACTIVE_LOW>;
		avdd-supply = <&vreg_l16b_2p8>;
		dvdd-supply = <&vreg_l11b_1p0>;
		dovdd-supply = <&vreg_l4b_1p8>;
		orientation = <0>;
		rotation = <180>;

		port {
			front_camera_out: endpoint {
				remote-endpoint = <&csiphy5_in>;
				data-lanes = <1 2 3 4>;
				link-frequencies = /bits/ 64 <368000000>;
			};
		};
	};
};

&pm8550ve_gpios {
	camera_rear_reset_default: camera-rear-reset-state {
		pins = "gpio5";
		function = "normal";
		power-source = <1>;
		bias-disable;
		output-low;
		qcom,drive-strength = <2>;
	};
};

&qupv3_2 {
	status = "okay";
};

&i2c3 {
	status = "okay";

	/* USB subsystem of the WCD939x codec: switches the SBU pins */
	wcd_usbss: typec-mux@e {
		compatible = "qcom,wcd9395-usbss", "qcom,wcd9390-usbss";
		reg = <0xe>;

		vdd-supply = <&vreg_l15b_1p8>;

		mode-switch;
		orientation-switch;

		ports {
			#address-cells = <1>;
			#size-cells = <0>;

			port@0 {
				reg = <0>;

				wcd_usbss_sbu_mux: endpoint {
					remote-endpoint = <&pmic_glink_sbu>;
				};
			};
		};
	};
};

&i2c11 {
	status = "okay";

	/* Second LED string; the stock DT gives it no enable pins and the
	 * stock driver never programs its bias section. */
	ktz8868_slave: backlight@11 {
		compatible = "kinetic,ktz8868";
		reg = <0x11>;

		ktz8868_slave_led: led {
			function = LED_FUNCTION_BACKLIGHT;
			function-enumerator = <2>;
			color = <LED_COLOR_ID_WHITE>;
			led-sources = <0 1 2 4 5>;
		};
	};
};

&i2c_master_hub_0 {
	status = "okay";
};

&i2c_hub_0 {
	status = "okay";

	ktz8868_master: backlight@11 {
		compatible = "kinetic,ktz8868";
		reg = <0x11>;

		enable-gpios = <&tlmm 15 GPIO_ACTIVE_HIGH>;

		kinetic,enable-lcd-bias;

		ktz8868_master_led: led {
			function = LED_FUNCTION_BACKLIGHT;
			function-enumerator = <1>;
			color = <LED_COLOR_ID_WHITE>;
			led-sources = <0 1 2 4 5>;
		};

		lcd_vsn: outn {
			regulator-name = "lcd_vsn";
			enable-gpios = <&tlmm 14 GPIO_ACTIVE_HIGH>;
		};

		lcd_vsp: outp {
			regulator-name = "lcd_vsp";
			enable-gpios = <&tlmm 111 GPIO_ACTIVE_HIGH>;
		};
	};
};

&i2c_hub_2 {
	clock-frequency = <400000>;
	status = "okay";

	pps_cp_secondary: charger@6f {
		compatible = "southchip,sc8547a";
		reg = <0x6f>;
		southchip,secondary;
		southchip,battery-overvoltage-microvolt = <4850000>;
		southchip,ac-overvoltage-microvolt = <12000000>;
		southchip,input-overvoltage-microvolt = <10000000>;
		southchip,input-overcurrent-microamp = <4500000>;
	};
};

/*
 * CPS8601 inductive pen charger (TX coil for the stylus). Five TLMM lines
 * from the stock dtbo fragment@80: int 172, sleep 106, scan 56,
 * off_state 107, sw_en 105. The chip carries factory firmware; the
 * optional SRAM update image (wireless_pen/0/cps8601_firmware.bin) is
 * not required for first bring-up.
 */
&i2c_hub_3 {
	status = "okay";

	cps8601: pen-charger@41 {
		compatible = "oplus,wls-charger-cps8601";
		reg = <0x41>;

		int-gpios = <&tlmm 172 GPIO_ACTIVE_HIGH>;
		sleep-gpios = <&tlmm 106 GPIO_ACTIVE_HIGH>;
		scan-gpios = <&tlmm 56 GPIO_ACTIVE_HIGH>;
		/* tlmm 107 is the stock "wls_off_state" line: high = charge
		 * inhibit, low = allow (vendor GP_3).  It is NOT a boost
		 * enable -- the coil rail is hboost via ADSP glink. */
		off-state-gpios = <&tlmm 107 GPIO_ACTIVE_HIGH>;
		sw-en-gpios = <&tlmm 105 GPIO_ACTIVE_HIGH>;

		oplus,ocp-threshold = <500>;
		oplus,ovp-threshold = <12000>;
		oplus,lvp-threshold = <4000>;
		oplus,fod-threshold = <400>;
	};
};

&i2c_hub_4 {
	clock-frequency = <400000>;
	status = "okay";

	spk_amp3: audio-codec@34 {
		compatible = "awinic,aw88261";
		reg = <0x34>;
		#sound-dai-cells = <0>;
		dvdd-supply = <&spk_amp_dvdd>;
		firmware-name = "awinic/erhai/aw88261_acf.bin";
		sound-name-prefix = "Amp3";
		awinic,audio-channel = <3>;
	};

	spk_amp1: audio-codec@35 {
		compatible = "awinic,aw88261";
		reg = <0x35>;
		#sound-dai-cells = <0>;
		dvdd-supply = <&spk_amp_dvdd>;
		firmware-name = "awinic/erhai/aw88261_acf.bin";
		sound-name-prefix = "Amp1";
		awinic,audio-channel = <1>;
	};

	spk_amp5: audio-codec@36 {
		compatible = "awinic,aw88261";
		reg = <0x36>;
		#sound-dai-cells = <0>;
		dvdd-supply = <&spk_amp_dvdd>;
		firmware-name = "awinic/erhai/aw88261_acf.bin";
		sound-name-prefix = "Amp5";
		awinic,audio-channel = <5>;
	};
};

&i2c_hub_8 {
	clock-frequency = <400000>;
	status = "okay";

	pps_cp_primary: charger@6f {
		compatible = "southchip,sc8547a";
		reg = <0x6f>;
		interrupt-parent = <&tlmm>;
		interrupts = <163 IRQ_TYPE_EDGE_FALLING>;
		pinctrl-names = "default";
		pinctrl-0 = <&pps_cp_irq_default>;
		southchip,battery-overvoltage-microvolt = <4850000>;
		southchip,ac-overvoltage-microvolt = <12000000>;
		southchip,input-overvoltage-microvolt = <10000000>;
		southchip,input-overcurrent-microamp = <4500000>;
	};
};

&i2c_hub_9 {
	clock-frequency = <400000>;
	status = "okay";

	spk_amp0: audio-codec@34 {
		compatible = "awinic,aw88261";
		reg = <0x34>;
		#sound-dai-cells = <0>;
		dvdd-supply = <&spk_amp_dvdd>;
		firmware-name = "awinic/erhai/aw88261_acf.bin";
		sound-name-prefix = "Amp0";
		awinic,audio-channel = <0>;
	};

	spk_amp2: audio-codec@35 {
		compatible = "awinic,aw88261";
		reg = <0x35>;
		#sound-dai-cells = <0>;
		dvdd-supply = <&spk_amp_dvdd>;
		firmware-name = "awinic/erhai/aw88261_acf.bin";
		sound-name-prefix = "Amp2";
		awinic,audio-channel = <2>;
	};

	spk_amp6: audio-codec@36 {
		compatible = "awinic,aw88261";
		reg = <0x36>;
		#sound-dai-cells = <0>;
		dvdd-supply = <&spk_amp_dvdd>;
		firmware-name = "awinic/erhai/aw88261_acf.bin";
		sound-name-prefix = "Amp6";
		awinic,audio-channel = <6>;
	};
};

&iris {
	firmware-name = "qcom/sm8750/erhai/vpu35_4v.mbn";

	status = "okay";
};

&mdss {
	status = "okay";
};

&mdss_dp0 {
	status = "okay";
};

&mdss_dp0_out {
	link-frequencies = /bits/ 64 <1620000000 2700000000 5400000000 8100000000>;
};

&mdss_dsi0 {
	vdda-supply = <&vreg_l3g_1p2>;

	qcom,dual-dsi-mode;
	qcom,sync-dual-dsi;
	qcom,master-dsi;

	status = "okay";

	panel: panel@0 {
		compatible = "csot,xn242", "novatek,nt36536";
		reg = <0>;

		reset-gpios = <&tlmm 98 GPIO_ACTIVE_LOW>;

		/* The panel drives TE on gpio86 (mdp_vsync); the DPU video engine
		 * syncs to it by default (DPU_VSYNC_SOURCE_GPIO_0). Without it
		 * no frame ever completes (vblank timeouts, black screen). */
		pinctrl-0 = <&mdp_te_vsync>;
		pinctrl-names = "default";
		vddio-supply = <&vreg_l12b_1p8>;
		vsn-supply = <&lcd_vsn>;
		vsp-supply = <&lcd_vsp>;

		backlight = <&panel_backlight>;

		ports {
			#address-cells = <1>;
			#size-cells = <0>;

			port@0 {
				reg = <0>;

				panel0_in: endpoint {
					remote-endpoint = <&mdss_dsi0_out>;
				};
			};

			port@1 {
				reg = <1>;

				panel1_in: endpoint {
					remote-endpoint = <&mdss_dsi1_out>;
				};
			};
		};
	};
};

&mdss_dsi0_out {
	remote-endpoint = <&panel0_in>;
	data-lanes = <0 1 2 3>;
};

&mdss_dsi0_phy {
	vdds-supply = <&vreg_l3i_0p88>;

	status = "okay";
};

&mdss_dsi1 {
	vdda-supply = <&vreg_l3g_1p2>;

	qcom,dual-dsi-mode;
	qcom,sync-dual-dsi;

	/* DSI1 is the slave link; use DSI0's PLL clocks */
	clocks = <&dispcc DISP_CC_MDSS_BYTE1_CLK>,
		 <&dispcc DISP_CC_MDSS_BYTE1_INTF_CLK>,
		 <&dispcc DISP_CC_MDSS_PCLK1_CLK>,
		 <&dispcc DISP_CC_MDSS_ESC1_CLK>,
		 <&dispcc DISP_CC_MDSS_AHB_CLK>,
		 <&gcc GCC_DISP_HF_AXI_CLK>,
		 <&mdss_dsi0_phy DSI_PIXEL_PLL_CLK>,
		 <&mdss_dsi0_phy DSI_BYTE_PLL_CLK>,
		 <&dispcc DISP_CC_ESYNC1_CLK>,
		 <&dispcc DISP_CC_OSC_CLK>,
		 <&dispcc DISP_CC_MDSS_BYTE1_CLK_SRC>,
		 <&dispcc DISP_CC_MDSS_PCLK1_CLK_SRC>;

	status = "okay";
};

&mdss_dsi1_out {
	remote-endpoint = <&panel1_in>;
	data-lanes = <0 1 2 3>;
};

&mdss_dsi1_phy {
	vdds-supply = <&vreg_l3i_0p88>;

	status = "okay";
};

&gpi_dma1 {
	status = "okay";
};

&gpi_dma2 {
	status = "okay";
};

&pm8550_gpios {
	volume_down_n: volume-down-n-state {
		pins = "gpio6";
		function = "normal";
		bias-pull-up;
		input-enable;
		power-source = <1>;
	};
};

&pm8550_temp_alarm {
	io-channels = <&pmk8550_vadc 0x103>;
	io-channel-names = "thermal";
};

&pmih0108_eusb2_repeater {
	qcom,tune-usb2-preem = /bits/ 8 <0x3>;
	qcom,tune-usb2-amplitude = /bits/ 8 <0xb>;
	qcom,tune-usb2-disc-thres = /bits/ 8 <0x7>;
	qcom,squelch-detector-bp = <(-2000)>;

	vdd18-supply = <&vreg_l15b_1p8>;
	vdd3-supply = <&vreg_l5b_3p1>;

	status = "okay";
};

&pmk8550_vadc {
	channel@3 {
		reg = <0x3>;
		label = "pmk8550-die";
		qcom,pre-scaling = <1 1>;
	};

	channel@44 {
		reg = <0x44>;
		label = "xo-therm";
		qcom,pre-scaling = <1 1>;
		qcom,ratiometric;
		qcom,hw-settle-time = <200>;
		qcom,adc-tm;
	};

	channel@103 {
		reg = <0x103>;
		label = "pm8550-die";
		qcom,pre-scaling = <1 1>;
	};

	channel@144 {
		reg = <0x144>;
		label = "skin-therm";
		qcom,pre-scaling = <1 1>;
		qcom,ratiometric;
		qcom,hw-settle-time = <200>;
		qcom,adc-tm;
	};

	channel@149 {
		reg = <0x149>;
		label = "gpio2-therm";
		qcom,pre-scaling = <1 1>;
		qcom,ratiometric;
		qcom,hw-settle-time = <200>;
		qcom,adc-tm;
	};
};

&pmk8550_rtc {
	nvmem-cells = <&rtc_offset>;
	nvmem-cell-names = "offset";
};

&pmk8550_sdam_2 {
	rtc_offset: rtc-offset@bc {
		reg = <0xbc 0x4>;
	};
};

&pon_pwrkey {
	status = "okay";
};

&pon_resin {
	linux,code = <KEY_VOLUMEUP>;
	status = "okay";
};

&q6apmbedai {
	#address-cells = <1>;
	#size-cells = <0>;

	dai@28 {
		reg = <SECONDARY_TDM_RX_0>;
		clocks = <&q6prmcc LPASS_CLK_ID_SEC_TDM_IBIT LPASS_CLK_ATTRIBUTE_COUPLE_NO>;
		clock-names = "bclk";
	};
};

&qupv3_1 {
	status = "okay";
};

&adspslpi_mem {
	/*
	 * The stock ADSP firmware spans 80.5M from the 0x9ee00000 bank base
	 * (stock adspslpi is 0x5080000); the upstream 58.5M window makes the
	 * mdt loader reject the image as "segment outside memory range".
	 */
	reg = <0x0 0x9ee00000 0x0 0x5080000>;
};

&remoteproc_soccp {
	firmware-name = "qcom/sm8750/erhai/soccp.mbn";
};

&remoteproc_adsp {
	firmware-name = "qcom/sm8750/erhai/adsp.mdt",
			"qcom/sm8750/erhai/adsp_dtb.mdt";

	status = "okay";
};

&spi4 {
	status = "okay";

	pinctrl-0 = <&qupv3_se4_spi>;
	pinctrl-names = "default";

	touchscreen@0 {
		compatible = "novatek,nt36536-ts";
		reg = <0>;
		spi-max-frequency = <12000000>;

		pinctrl-0 = <&nt36536_int>;
		pinctrl-names = "default";

		interrupt-parent = <&tlmm>;
		interrupts = <162 IRQ_TYPE_EDGE_FALLING>;

		panel = <&panel>;

		/*
		 * The controller reports in its 2400x3392 portrait frame and
		 * the panel scans landscape. The controller's X axis is
		 * mirrored first and the axes are then swapped (the generic
		 * properties invert before they swap). Measured with the USB
		 * port on the right: left to right raises X, top to bottom
		 * raises Y.
		 */
		touchscreen-size-x = <2400>;
		touchscreen-size-y = <3392>;
		/* the 193 x 274 mm active area, along the controller axes */
		touchscreen-x-mm = <193>;
		touchscreen-y-mm = <274>;
		touchscreen-swapped-x-y;
		touchscreen-inverted-x;
		firmware-name = "novatek/nt36536-xn242.bin";
		novatek,pen-support;
	};
};

/* The external speaker amplifiers use TDM, not the WSA SoundWire paths. */
&lpass_wsamacro {
	status = "disabled";
};

&lpass_wsa2macro {
	status = "disabled";
};

&swr1 {
	status = "okay";

	wcd_rx: codec@0,4 {
		compatible = "sdw20217010e00";
		reg = <0 4>;
		qcom,rx-port-mapping = <1 2 3 4 5 9>;
	};
};

&swr2 {
	status = "okay";

	/* The TX controller has one output port before its four input ports. */
	qcom,dout-ports = <1>;
	qcom,ports-sinterval-low =	/bits/ 8 <0x00 0x01 0x01 0x03 0x03>;
	qcom,ports-offset1 =		/bits/ 8 <0x00 0x00 0x00 0x01 0x01>;
	qcom,ports-offset2 =		/bits/ 8 <0x00 0x00 0x00 0x00 0x00>;
	qcom,ports-hstart =		/bits/ 8 <0xff 0xff 0xff 0xff 0xff>;
	qcom,ports-hstop =		/bits/ 8 <0xff 0xff 0xff 0xff 0xff>;
	qcom,ports-word-length =	/bits/ 8 <0xff 0xff 0xff 0xff 0xff>;
	qcom,ports-block-pack-mode =	/bits/ 8 <0xff 0xff 0xff 0xff 0xff>;
	qcom,ports-block-group-count =	/bits/ 8 <0xff 0xff 0xff 0xff 0xff>;
	qcom,ports-lane-control =	/bits/ 8 <0xff 0x01 0x02 0x00 0x00>;

	wcd_tx: codec@0,3 {
		compatible = "sdw20217010e00";
		reg = <0 3>;
		qcom,tx-port-mapping = <2 2 3 4>;
	};
};

&tlmm {
	/* reserved for secure world */
	gpio-reserved-ranges = <36 4>, <74 1>;

	pps_cp_irq_default: pps-cp-irq-default-state {
		pins = "gpio163";
		function = "gpio";
		bias-pull-up;
		drive-strength = <2>;
	};

	qupv3_se4_spi: qupv3-se4-spi-state {
		miso-pins {
			pins = "gpio48";
			function = "qup1_se4";
			drive-strength = <6>;
			bias-disable;
		};

		mosi-pins {
			pins = "gpio49";
			function = "qup1_se4";
			drive-strength = <4>;
			bias-disable;
		};

		clk-pins {
			pins = "gpio50";
			function = "qup1_se4";
			drive-strength = <6>;
			bias-disable;
		};

		cs-pins {
			pins = "gpio51";
			function = "qup1_se4";
			drive-strength = <4>;
			bias-disable;
		};
	};

	nt36536_int: nt36536-int-state {
		pins = "gpio162";
		function = "gpio";
		drive-strength = <8>;
		bias-disable;
	};
	wlan_en: wlan-en-state {
		pins = "gpio16";
		function = "gpio";
		drive-strength = <8>;
		bias-pull-down;
	};
	mdp_te_vsync: mdp-te-vsync-state {
		pins = "gpio86";
		function = "mdp_vsync";
		drive-strength = <2>;
		bias-pull-down;
	};

	wcd_reset_default: wcd-reset-default-state {
		pins = "gpio101";
		function = "gpio";
		drive-strength = <6>;
		bias-disable;
	};

	sec_tdm_active: sec-tdm-active-state {
		sck-pins {
			pins = "gpio121";
			function = "i2s1_sck";
			drive-strength = <6>;
			bias-disable;
		};

		data0-pins {
			pins = "gpio122";
			function = "i2s1_data0";
			drive-strength = <6>;
			bias-disable;
		};

		ws-pins {
			pins = "gpio123";
			function = "i2s1_ws";
			drive-strength = <6>;
			bias-disable;
		};

		data1-pins {
			pins = "gpio124";
			function = "i2s1_data1";
			drive-strength = <6>;
			bias-pull-down;
		};
	};

	hall_sensor_default: hall-sensor-default-state {
		pins = "gpio97";
		function = "gpio";
		drive-strength = <2>;
		bias-disable;
	};

	pogo_kb_detect: pogo-kb-detect-state {
		pins = "gpio96";
		function = "gpio";
		drive-strength = <2>;
		bias-pull-up;
	};

	/*
	 * The keyboard data line is shared by TX and RX through a direction
	 * switch, so neither pin gets a pull. With the port closed, TX is left
	 * as a floating GPIO like on the stock firmware.
	 */
	pogo_kb_uart_default: pogo-kb-uart-default-state {
		tx-pins {
			pins = "gpio2";
			function = "qup2_se0";
			drive-strength = <8>;
			bias-disable;
		};

		rx-pins {
			pins = "gpio3";
			function = "qup2_se0";
			drive-strength = <2>;
			bias-disable;
		};
	};

	pogo_kb_uart_sleep: pogo-kb-uart-sleep-state {
		tx-pins {
			pins = "gpio2";
			function = "gpio";
			drive-strength = <8>;
			bias-disable;
		};

		rx-pins {
			pins = "gpio3";
			function = "qup2_se0";
			drive-strength = <2>;
			bias-disable;
		};
	};
	camera_front_reset_default: camera-front-reset-state {
		pins = "gpio7";
		function = "gpio";
		drive-strength = <2>;
		bias-disable;
		output-low;
	};
};

&uart7 {
	status = "okay";
};

&ufs_mem_hc {
	reset-gpios = <&tlmm 215 GPIO_ACTIVE_LOW>;

	vcc-supply = <&vreg_l17b_2p5>;
	vcc-max-microamp = <1300000>;
	vccq-supply = <&vreg_l1d_1p2>;
	vccq-max-microamp = <1200000>;

	status = "okay";
};

&pcie0 {
	pinctrl-0 = <&pcie0_default_state>;
	pinctrl-names = "default";

	status = "okay";
};

&pcie0_phy {
	vdda-phy-supply = <&vreg_l1f_0p88>;
	vdda-pll-supply = <&vreg_l3g_1p2>;

	status = "okay";
};

&pcieport0 {
	wake-gpios = <&tlmm 104 GPIO_ACTIVE_LOW>;
	reset-gpios = <&tlmm 102 GPIO_ACTIVE_LOW>;

	wifi@0 {
		compatible = "pci17cb,110e";
		reg = <0x10000 0x0 0x0 0x0 0x0>;

		vddaon-supply = <&vreg_pmu_aon_0p59>;
		vddwlcx-supply = <&vreg_pmu_wlcx_0p8>;
		vddwlmx-supply = <&vreg_pmu_wlmx_0p85>;
		vddrfa0p9-supply = <&vreg_pmu_rfa_0p8>;
		vddrfa1p3-supply = <&vreg_pmu_rfa_1p2>;
		vddrfa1p9-supply = <&vreg_pmu_rfa_1p8>;
		vddpcie0p9-supply = <&vreg_pmu_pcie_0p9>;
		vddpcie1p2-supply = <&vreg_pmu_pcie_1p8>;
	};
};

&gpu {
	status = "okay";
};

&gunyah_hyp_mem {
	reg = <0x0 0x80000000 0x0 0x1200000>;
};

&gpu_zap_shader {
	firmware-name = "qcom/sm8750/erhai/gen80000_zap.mbn";
};

&uart_kb {
	pinctrl-0 = <&pogo_kb_uart_default>;
	pinctrl-1 = <&pogo_kb_uart_sleep>;
	pinctrl-names = "default", "sleep";

	status = "okay";

	keyboard {
		compatible = "oneplus,pad2pro-pogo-keyboard";

		vdd-supply = <&pogo_kb_pwr>;
		tx-enable-gpios = <&tlmm 83 GPIO_ACTIVE_HIGH>;
		detect-gpios = <&tlmm 96 GPIO_ACTIVE_LOW>;
		interrupts-extended = <&tlmm 96 IRQ_TYPE_EDGE_FALLING>;
		current-speed = <921600>;
		wakeup-source;

		pinctrl-0 = <&pogo_kb_detect>;
		pinctrl-names = "default";
	};
};

&uart14 {
	pinctrl-0 = <&qup_uart14_default>, <&qup_uart14_cts_rts>;
	pinctrl-names = "default";

	status = "okay";

	bluetooth {
		compatible = "qcom,wcn7860-bt";

		vddaon-supply = <&vreg_pmu_aon_0p59>;
		vddbtcx-supply = <&vreg_pmu_wlcx_0p8>;
		vddbtcmx-supply = <&vreg_pmu_wlmx_0p85>;
		vddrfa0p9-supply = <&vreg_pmu_rfa_0p8>;
		vddrfa1p3-supply = <&vreg_pmu_rfa_1p2>;
		vddrfa1p9-supply = <&vreg_pmu_rfa_1p8>;

		max-speed = <3200000>;
	};
};

&ufs_mem_phy {
	vdda-phy-supply = <&vreg_l1j_0p91>;
	vdda-pll-supply = <&vreg_l3g_1p2>;

	status = "okay";
};

&usb {
	/* role follows the pmic-glink Type-C notifications now that ADSP runs */
	status = "okay";
};

&usb_dp_qmpphy {
	vdda-phy-supply = <&vreg_l3g_1p2>;
	vdda-pll-supply = <&vreg_l2d_0p88>;

	status = "okay";
};

&usb_dp_qmpphy_out {
	remote-endpoint = <&pmic_glink_ss_in>;
};

&usb_dwc3_hs {
	remote-endpoint = <&pmic_glink_hs_in>;
};

&usb_hsphy {
	vdd-supply = <&vreg_l2d_0p88>;
	vdda12-supply = <&vreg_l3g_1p2>;

	phys = <&pmih0108_eusb2_repeater>;

	status = "okay";
};

&pm8550ve_f_gpios {
	bt_default: bt-default-state {
		pins = "gpio3";
		function = "normal";
		power-source = <1>;
		bias-disable;
		input-disable;
		output-enable;
	};
};

&smp2p_soccp {
	status = "okay";
};

&remoteproc_soccp {
	status = "okay";
};
